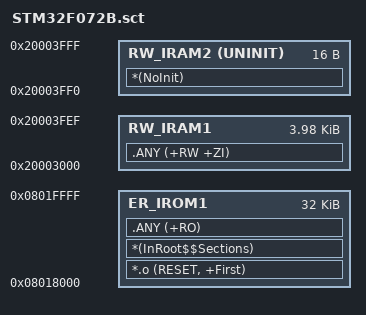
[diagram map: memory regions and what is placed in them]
; *************************************************************
; *** Scatter-Loading Description File generated by uVision ***
; *************************************************************

LR_IROM1 0x08018000 0x00008000  {    ; load region size_region
  ER_IROM1 0x08018000 0x00008000  {  ; load address = execution address
   *.o (RESET, +First)
   *(InRoot$$Sections)
   .ANY (+RO)
  }
  RW_IRAM1 0x20003000 0x00000FF0  {  ; RW data
   .ANY (+RW +ZI)
  }
  RW_IRAM2 0x20003FF0 UNINIT 0x00000010  {
   *(NoInit)
  }
}

